# AE402FA0E5597BE0_CM55_HE_View register map
Vendor: Alif Semiconductor; Series: E4; File version: 1.0
CPU: CM55 r1p0, selectable endian, MPU, FPU, double-precision FPU, DSP, VTOR, 8 interrupt priority bits, 1 SAU regions
Registers are 32-bit, read-write, reset 0x0 unless marked. A register's access mark holds for its fields unless they carry their own. Offsets are from the block's base; [hi:lo] are bit positions; {n}, {i} and the like mark numbered series; <NAME> marks a mode.

## ETH (part 2 of 4)
Base 0x48100000
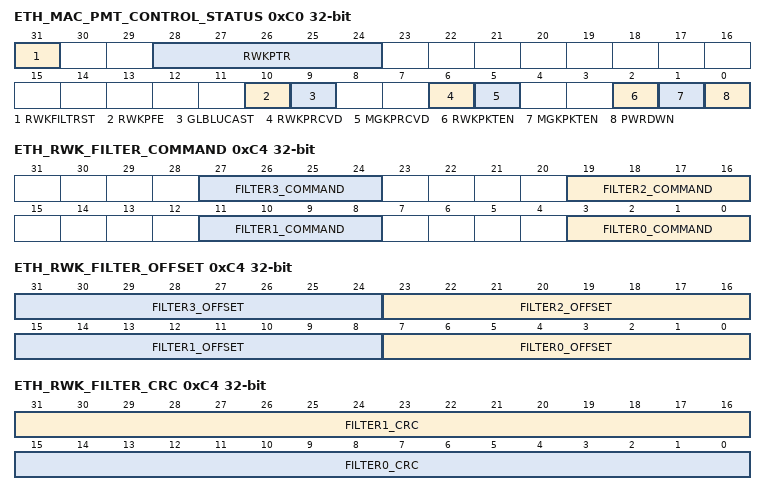
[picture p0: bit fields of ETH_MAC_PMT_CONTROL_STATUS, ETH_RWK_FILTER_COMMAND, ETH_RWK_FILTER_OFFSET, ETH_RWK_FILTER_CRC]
0xC0 ETH_MAC_PMT_CONTROL_STATUS — PMT Control and Status Register
  [31] RWKFILTRST — Remote Wake-Up Packet Filter Register Pointer Reset When this bit is set, the remote wake-up packet filter register pointer is reset to 0x0. It is automatically cleared after 1 clock cycle. Access restriction applies. Setting 1 sets. Self-cleared. Setting 0 has no effect.
    0=Remote wake-up packet filter register pointer is not reset; 1=Remote wake-up packet filter register pointer is reset
  [28:24] RWKPTR ro — Remote Wake-up FIFO Pointer This field gives the current value of the Remote Wake-up Packet Filter register pointer.
  [10] RWKPFE — Remote Wake-up Packet Forwarding Enable When this bit is set along with RWKPKTEN, the MAC receiver drops all received frames until it receives the expected wake-up frame. All frames after that event including the received wake-up frame are forwarded to application. This bit is then self-cleared on receiving the wake-up packet. The application can also clear this bit before the expected wake-up frame is received. In such cases, the MAC reverts to the default behavior where packets received are forwarded to the application. This bit must only be set when RWKPKTEN is set high and PWRDWN is set low. The setting of this bit has no effect when PWRDWN is set high. Note: If Magic Packet Enable and Wake-Up Frame Enable are both set along with setting of this bit and Magic Packet is received prior to wake-up frame, this bit is self-cleared on receiving Magic Packet, the received Magic packet is dropped, and all frames after received Magic Packet are forwarded to application. Access restriction applies. Setting 1 sets. Self-cleared. Setting 0 has no effect.
    0=Remote wake-up packet forwarding is disabled; 1=Remote wake-up packet forwarding is enabled
  [9] GLBLUCAST — Global Unicast When this bit set, any unicast packet filtered by the MAC (DAF) address recognition is detected as a remote wake-up packet.
    0=Global unicast is disabled; 1=Global unicast is enabled
  [6] RWKPRCVD ro — Remote Wake-Up Packet Received When this bit is set, it indicates that the power management event is generated because of the reception of a remote wake-up packet. This bit is cleared when this register is read. Access restriction applies. Clears on read or write of 1 when the ETH_MAC_CSR_SW_CTRL[RCWE] bit is set. Self-set to 1 on internal event.
    0=Remote wake-up packet is received; 1=Remote wake-up packet is received
  [5] MGKPRCVD ro — Magic Packet Received When this bit is set, it indicates that the power management event is generated because of the reception of a magic packet. This bit is cleared when this register is read. Access restriction applies. Clears on read or write of 1 when the ETH_MAC_CSR_SW_CTRL[RCWE] bit is set. Self-set to 1 on internal event.
    0=No magic packet is received; 1=Magic packet is received
  [2] RWKPKTEN — Remote Wake-Up Packet Enable When this bit is set, a power management event is generated when the MAC receives a remote wake-up packet.
    0=Remote wake-up packet is disabled; 1=Remote wake-up packet is enabled
  [1] MGKPKTEN — Magic Packet Enable When this bit is set, a power management event is generated when the MAC receives a magic packet.
    0=Magic packet is disabled; 1=Magic packet is enabled
  [0] PWRDWN — Power Down When this bit is set, the MAC receiver drops all received packets until it receives the expected magic packet or remote wake-up packet. This bit is then self-cleared and the power-down mode is disabled. The software can clear this bit before the expected magic packet or remote wake-up packet is received. The packets received by the MAC after this bit is cleared are forwarded to the application. This bit must only be set when the MGKPKTEN, GLBLUCAST, or RWKPKTEN bit is set high. Note: The user can gate-off the CLK_CSR during power-down mode. However, when the CLK_CSR is gated-off, the user cannot perform any read or write operations on this register. Therefore, software cannot clear this bit. Access restriction applies. Setting 1 sets. Self-cleared. Setting 0 has no effect.
    0=Power down is disabled; 1=Power down is enabled
0xC4 ETH_RWK_PACKET_FILTER — Remote Wakeup Filter Byte Mask Register
  [31:0] WKUPFRMFTR — RWK Packet Filter This field contains the various controls of RWK Packet filter.
0xC4 ETH_RWK_FILTER_BYTE_MASK (alternate view of ETH_RWK_PACKET_FILTER) — Remote Wakeup Filter Byte Mask Register
  [31:0] FILTER_BYTE_MASK — Filter0 to Filter3 32-bit Mask This field defines the bytes of the packet that are examined by the corresponding filter (0 to 3) to determine whether or not a packet is a wake-up packet. Bit 31 must be zero. Bits [30-0] are the byte mask. Each bit in this mask corresponds to one byte in the detected packet. If the bit is 1, the corresponding byte is taken into the CRC16 calculation.
0xC4 ETH_RWK_FILTER_COMMAND (alternate view of ETH_RWK_PACKET_FILTER) — Remote Wakeup Filter Command Register
  [8n+3:8n] FILTER{n}_COMMAND (n=0..3) — Filter{n} Command The 4-bit filter command controls the filter operation. Bit {8n+3} specifies the address type, defining the destination address type of the pattern. When the bit is set, the pattern applies to only multicast packets; when the bit is reset, the pattern applies only to unicast packet. Bit {8n+2} (Inverse Mode), when set, reverses the logic of the CRC16 hash function signal, to reject a packet with matching CRC_16 value. Bit {8n+2}, along with Bit {8n+1}, allows a MAC to reject a subset of remote wake-up packets by creating filter logic such as Pattern 1 AND NOT Pattern 2. Bit {8n+1} (And_Previous) implements the Boolean logic. When set, the result of the current entry is logically ANDed with the result of the previous filter. This AND logic allows a filter pattern longer than 32 bytes by splitting the mask among two, three, or four filters. This depends on the number of filters that have the And_Previous bit set. Bit {8n} is the enable for filter. If Bit {8n} is not set, filter is disabled.
0xC4 ETH_RWK_FILTER_OFFSET (alternate view of ETH_RWK_PACKET_FILTER) — Remote Wakeup Filter Offset Register
  [8n+7:8n] FILTER{n}_OFFSET (n=0..3) — Filter{n} Offset This filter offset defines the offset (within the packet) from which the filter examines the packets. This 8-bit pattern-offset is the offset for the filter first byte to be examined. The minimum allowed offset is 12, which refers to the 13th byte of the packet. The offset value 0 refers to the first byte of the packet.
0xC4 ETH_RWK_FILTER_CRC (alternate view of ETH_RWK_PACKET_FILTER) — Remote Wakeup Filter CRC-16 Register
  [31:16] FILTER1_CRC — Filter1 CRC-16 This filter CRC-16 contains the CRC_16 value of the pattern. The 16-bit CRC calculation uses the following polynomial: G(x) = x^16 + x^15 + x^2 + 1
  [15:0] FILTER0_CRC — Filter0 CRC-16 This filter CRC-16 contains the CRC_16 value of the pattern. The 16-bit CRC calculation uses the following polynomial: G(x) = x^16 + x^15 + x^2 + 1
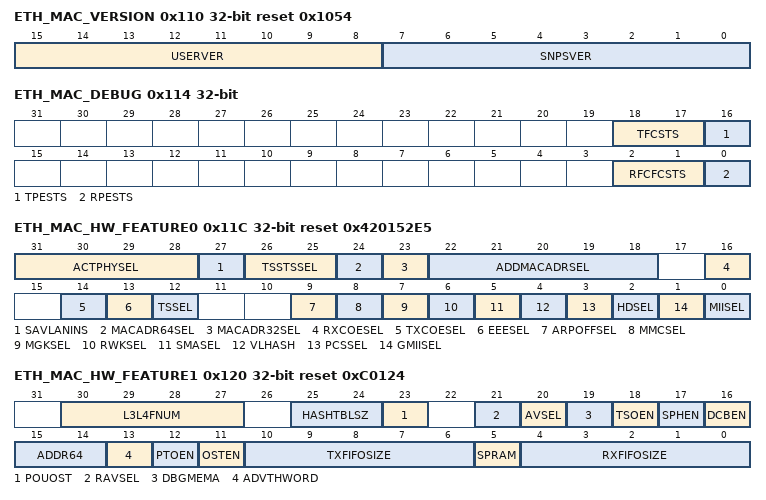
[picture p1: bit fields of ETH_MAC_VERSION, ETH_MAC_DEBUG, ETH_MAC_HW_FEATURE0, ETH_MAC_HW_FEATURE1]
0x110 ETH_MAC_VERSION ro reset 0x1054 — Module Version Register
  [15:8] USERVER — User-defined version
  [7:0] SNPSVER — Vendor-defined version
0x114 ETH_MAC_DEBUG ro — Debug Register
  [18:17] TFCSTS — Reserved
  [16] TPESTS — MAC RMII Transmit Protocol Engine Status When this bit is set, it indicates that the MAC RMII transmit protocol engine is actively transmitting data, and it is not in the Idle state.
    0=MAC RMII transmit protocol engine status not detected; 1=MAC RMII transmit protocol engine status detected
  [2:1] RFCFCSTS — Reserved
  [0] RPESTS — MAC RMII Receive Protocol Engine Status When this bit is set, it indicates that the MAC RMII receive protocol engine is actively receiving data, and it is not in the Idle state.
    0=MAC RMII receive protocol engine status not detected; 1=MAC RMII receive protocol engine status detected
0x11C ETH_MAC_HW_FEATURE0 ro reset 0x420152E5 — ETH Hardware Feature Register 0
  [31:28] ACTPHYSEL — Active PHY Selected
    4=RMII
  [27] SAVLANINS — Source Address or VLAN Insertion Enable
    0=Source address or VLAN insertion disabled
  [26:25] TSSTSSEL — Timestamp System Time Source
    1=Internal
  [24] MACADR64SEL — MAC Addresses 64-127 Selected
    0=MAC addresses 64-127 disabled
  [23] MACADR32SEL — MAC Addresses 32-63 Selected
    0=MAC addresses 32-63 disabled
  [22:18] ADDMACADRSEL — MAC Addresses 1-31 Selected
    0=MAC addresses 1-31 disabled
  [16] RXCOESEL — Receive Checksum Offload Enabled
    1=Receive checksum offload enabled
  [14] TXCOESEL — Transmit Checksum Offload Enabled
    1=Transmit checksum offload enabled
  [13] EEESEL — Energy Efficient Ethernet Enabled
    0=Energy efficient ethernet disabled
  [12] TSSEL — IEEE 1588-2008 Timestamp Enabled
    1=IEEE 1588-2008 timestamp enabled
  [9] ARPOFFSEL — ARP Offload Enabled
    1=ARP offload disabled
  [8] MMCSEL — RMON Module Enable
    0=RMON module disabled
  [7] MGKSEL — PMT Magic Packet Enable
    1=PMT magic packet enabled
  [6] RWKSEL — PMT Remote Wake-up Packet Enable
    1=PMT remote wake-up packet enabled
  [5] SMASEL — SMA (MDIO) Interface
    1=SMA (MDIO) interface selected
  [4] VLHASH — VLAN Hash Filter Selected
    0=VLAN hash filter not selected
  [3] PCSSEL — PCS Registers (TBI, SGMII, or RTBI PHY interface)
    0=No PCS registers (TBI, SGMII, or RTBI PHY interface)
  [2] HDSEL — Half-duplex Support
    1=Half-duplex supported
  [1] GMIISEL — 1000 Mbps Support
    0=No 1000 Mbps supported
  [0] MIISEL — 10 or 100 Mbps Support
    1=10 or 100 Mbps supported
0x120 ETH_MAC_HW_FEATURE1 ro reset 0xC0124 — ETH Hardware Feature Register 1
  [30:27] L3L4FNUM — Total number of L3 or L4 Filters
    0=No L3 or L4 filter
  [25:24] HASHTBLSZ — Hash Table Size
    0=No hash table
  [23] POUOST — One Step for PTP over UDP/IP Enable
    0=One step for PTP over UDP/IP is disabled
  [21] RAVSEL — Rx Side Only AV Enable
    0=Rx side only AV is disabled
  [20] AVSEL — AV Enable
    0=AV fature is disabled
  [19] DBGMEMA — DMA Debug Registers Enable
    1=DMA debug registers enabled
  [18] TSOEN — TCP Segmentation Offload Enable
    1=TCP segmentation offload is enabled
  [17] SPHEN — Split Header Enable
    0=Split header is disabled
  [16] DCBEN — DCB Enable
    0=DCB is not selected
  [15:14] ADDR64 — Address Width.
    0=32
  [13] ADVTHWORD — IEEE 1588 High Word Register Enable
    0=IEEE 1588 high word register is disabled
  [12] PTOEN — PTP Offload Enable
    0=PTP offload is disabled
  [11] OSTEN — One-Step Timestamping Enable
    0=One-step timestamping is disabled
  [10:6] TXFIFOSIZE — MTL Transmit FIFO Size
    4=2048 bytes
  [5] SPRAM — Single Port RAM Enable
    1=Single port RAM is enabled
  [4:0] RXFIFOSIZE — MTL Receive FIFO Size
    4=2048 bytes
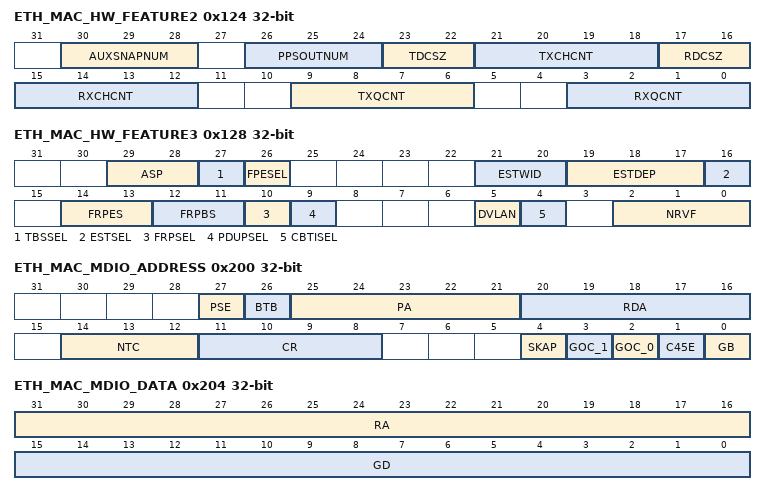
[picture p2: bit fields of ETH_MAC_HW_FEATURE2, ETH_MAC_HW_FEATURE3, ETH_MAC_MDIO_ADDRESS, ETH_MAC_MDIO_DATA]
0x124 ETH_MAC_HW_FEATURE2 ro — ETH Hardware Feature Register 2
  [30:28] AUXSNAPNUM — Number of Auxiliary Snapshot Inputs
    0=No auxiliary input
  [26:24] PPSOUTNUM — Number of PPS Outputs
    0=No PPS output
  [23:22] TDCSZ — Tx DMA Descriptor Cache Size in terms of 16-bytes descriptors
    0=Cache not configured
  [21:18] TXCHCNT — Number of DMA Transmit Channels
    0=1 DMA Tx channel
  [17:16] RDCSZ — Rx DMA Descriptor Cache Size in terms of 16-bytes descriptors
    0=Cache not configured
  [15:12] RXCHCNT — Number of DMA Receive Channels
    0=1 DMA Rx channel
  [9:6] TXQCNT — Number of MTL Transmit Queues
    0=1 MTL Tx Queue
  [3:0] RXQCNT — Number of MTL Receive Queues
    0=1 MTL Rx Queue
0x128 ETH_MAC_HW_FEATURE3 ro — ETH Hardware Feature Register 3
  [29:28] ASP — Automotive Safety Package
    0=No safety features selected
  [27] TBSSEL — Time Based Scheduling Enable
    0=Time based scheduling disabled
  [26] FPESEL — Frame Preemption Enable
    0=Frame preemption disabled
  [21:20] ESTWID — Width of the Time Interval field in the Gate Control List
    0=Width not configured
  [19:17] ESTDEP — Depth of the Gate Control List
    0=No depth configured
  [16] ESTSEL — Enhancements to Scheduled Traffic Enable
    0=Enhancements to scheduling traffic disabled
  [14:13] FRPES — Flexible Receive Parser Table Entries size
    0=64 entries
  [12:11] FRPBS — Flexible Receive Parser Buffer size
    0=64 bytes
  [10] FRPSEL — Flexible Receive Parser Select
    0=Flexible receive parser disabled
  [9] PDUPSEL — Broadcast/Multicast Packet Duplication
    0=Broadcast/multicast packet duplication disabled
  [5] DVLAN — Double VLAN Tag Processing Select
    0=Double VLAN tag processing disabled
  [4] CBTISEL — Queue/Channel based VLAN tag insertion on Tx Enable
    0=Queue/Channel based VLAN tag insertion on Tx disabled
  [2:0] NRVF — Number of Extended VLAN Tag Filters Enable
    0=No extended Rx VLAN filters
0x12C ETH_MAC_HW_FEATURE4 ro — ETH Hardware Feature Register 3
  [1:0] PCSEL — Policing Counters Selected
    0=Policing counter feature is not selected
0x200 ETH_MAC_MDIO_ADDRESS — MDIO Address Register
  [27] PSE — Preamble Suppression Enable When this bit is set, the MDIO suppresses the 32-bit preamble and transmits MDIO packets with only 1 preamble bit. When this bit is 0, the MDIO packets always has 32 bits of preamble as defined in the IEEE specifications.
    0=Preamble suppression disabled; 1=Preamble suppression enabled
  [26] BTB — Back to Back Transactions When this bit is set and if NTC > 0, at the end of the frame transfer, MAC acknowledges the completion of a read or write command before transferring the trailing clocks. So, application can initiate the next command and MAC can execute it immediately without waiting for the transmission of the trailing clocks of the previous frame. When this bit is reset, MAC considers the read or write command to be complete, that is, MAC clears the GB field, only after generating the trailing clocks. This mode ensures that the NTC is always generated after each frame. Note: Program this field with a value 1, only when NTC > 0.
    0=Back to back transactions disabled; 1=Back to back transactions enabled
  [25:21] PA — Physical Layer Address Specifies the address of the PHY device, out of the 32 possible PHY devices. Note: The value programmed in the C45E field determines if the PHY device is Clause 45 capable or Clause 22 capable.
  [20:16] RDA — Register or Device Address - For Clause 22 PHY: Specifies the PHY register address of the selected PHY device. - For Clause 45 PHY: Specifies the selected MDIO device.
  [14:12] NTC — Number of Trailing Clocks This field controls the number of trailing clock cycles generated on ETH_MDC after the end of MDIO frame transfer. The valid values can be from 0 to 7. When this field is programmed with a value of 0x3, MAC generates three clock cycles on the ETH_MDC line after the end of MDIO frame transfer.
  [11:8] CR — CSR Clock (CLK_CSR) Range The CLK_CSR range selection determines the frequency of the MDC clock (ETH_MDC) according to the CLK_CSR frequency: The suggested range of CLK_CSR frequency applicable for each value (when Bit 11 = 0) ensures that the ETH_MDC is approximately between 1.0 MHz to 2.5 MHz freqency range. When Bit 11 is set, the user can achieve a higher frequency of the ETH_MDC than the frequency limit of 2.5 MHz (specified in the IEEE 802.3 Specification) and program a clock divider of lower value. For example, when CLK_CSR is of 100 MHz frequency and the user programs the CR field to 0xA, the resultant ETH_MDC is of 12.5 MHz which is beyond the range specified in IEEE 802.3 Specification. Program the following values only if the interfacing chips support faster MDC clocks:
    0=CLK_CSR = 60-100 MHz; ETH_MDC = CLK_CSR / 42; 1=CLK_CSR = 100-150 MHz; ETH_MDC = CLK_CSR / 62; 2=CLK_CSR = 20-35 MHz; ETH_MDC = CLK_CSR / 16; 3=CLK_CSR = 35-60 MHz; ETH_MDC = CLK_CSR / 26; 4=CLK_CSR = 150-250 MHz; ETH_MDC = CLK_CSR / 102; 5=CLK_CSR = 250-300 MHz; ETH_MDC = CLK_CSR / 124; 6=CLK_CSR = 300-500 MHz; ETH_MDC = CLK_CSR / 204; 7=CLK_CSR = 500-800 MHz; ETH_MDC = CLK_CSR / 324; 8=CLK_CSR / 4; 9=CLK_CSR / 6; 10=CLK_CSR / 8; 11=CLK_CSR / 10; 12=CLK_CSR / 12; 13=CLK_CSR / 14; 14=CLK_CSR / 16; 15=CLK_CSR / 18
  [4] SKAP — Skip Address Packet When this bit is set, the MDIO does not send the address packets before read, write, or post-read increment address packets. This bit is valid only when the C45E bit is set.
    0=Skip address packet is disabled; 1=Skip address packet is enabled
  [3] GOC_1 — Operation Command 1 This is the higher bit of the operation command to the PHY. GOC_1 and GOC_O are encoded as follows: 0x0: Reserved 0x1: Write 0x2: Post read increment address for Clause 45 PHY 0x3: Read GOC_1 is encoded as follows: 0x0: Operation command 1 is disabled 0x1: Operation command 1 is enabled
  [2] GOC_0 — Operation Command 0 This is the lower bit of the operation command to the PHY. When in MDIO mode (MDIO master) this bit along with GOC_1 determines the operation to be performed to the PHY.
    0=Operation command 0 is disabled; 1=Operation command 0 is enabled
  [1] C45E — Clause 45 PHY Enable When this bit is set, Clause 45 capable PHY is connected to MDIO. When this bit is reset, Clause 22 capable PHY is connected to MDIO.
    0=Clause 45 PHY is disabled; 1=Clause 45 PHY is enabled
  [0] GB — RMII Busy The application writes 1 to this bit to instruct the SMA to initiate a read or write access to the MDIO slave. The MAC writes 0 to this bit after the MDIO frame transfer is complete. Therefore, the application must modify the fields of the ETH_MAC_MDIO_ADDRESS and ETH_MAC_MDIO_DATA registers only when the value in this bit is 0. For write operation, application must follow these steps: - Write the 16-bit data in the ETH_MAC_MDIO_DATA[GD] field. - Update the ETH_MAC_MDIO_DATA[RA] field with the register address of the PHY. - Write 1 to this bit For read operation, application must follow these steps: - Update the ETH_MAC_MDIO_DATA[RA] field with the register address of the PHY. - Write 1 to this bit - Wait until MAC writes 0 to this bit. When MAC writes 0 to this bit, it implies that the data read from the PHY is available in the ETH_MAC_MDIO_DATA[GD] field and the read transfer is complete. Note: RA field is valid only when C45E field is 1. Note: Even if the addressed PHY is not present, there is no change in the functionality of this bit. Access restriction applies. Setting 1 sets. Self-cleared. Setting 0 has no effect.
    0=RMII busy is disabled; 1=RMII busy is enabled
0x204 ETH_MAC_MDIO_DATA — MDIO Data Register
  [31:16] RA — Register Address This field is valid only when the ETH_MAC_MDIO_ADDRESS[C45E] bit is set. It contains the Register Address in the PHY to which the MDIO frame is intended for.
  [15:0] GD — RMII Data This field contains the 16-bit data value read from the PHY after a Management Read operation or the 16-bit data value to be written to the PHY before a Management Write operation.
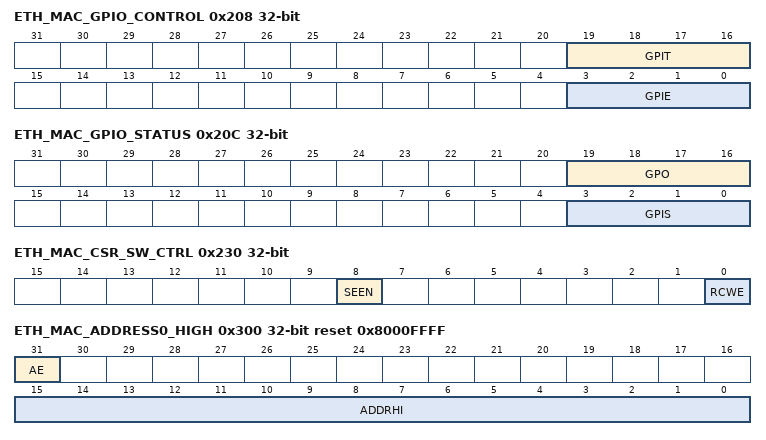
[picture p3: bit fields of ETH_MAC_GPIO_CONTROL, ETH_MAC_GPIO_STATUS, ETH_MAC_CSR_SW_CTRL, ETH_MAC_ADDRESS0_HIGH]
0x208 ETH_MAC_GPIO_CONTROL — GPIO Control Register
  [19:16] GPIT — GPI Type When a bit in this field is set, it indicates that the corresponding bit in the ETH_MAC_GPIO_STATUS[GPIS] field is of latched-low (LL) type. When a bit in this field is reset, it indicates that the corresponding bit in the ETH_MAC_GPIO_STATUS[GPIS] field is of latched-high (LH) type.
  [3:0] GPIE — GPI Interrupt Enable When a bit in this field is set and the programmed event (LL or LH) occurs on the corresponding bit in the ETH_MAC_GPIO_STATUS[GPIS] field, the ETH_MAC_INTERRUPT_STATUS[GPIIS] bit is set and an interrupt is generated on the ETH_SBD_IRQ signal. The ETH_MAC_INTERRUPT_STATUS[GPIIS] bit is cleared when the application reads the ETH_MAC_GPIO_STATUS[GPIS] field. When a bit in this field is reset, the ETH_MAC_INTERRUPT_STATUS[GPIIS] bit is not set when any event occurs on the corresponding bit in the ETH_MAC_GPIO_STATUS[GPIS] field.
0x20C ETH_MAC_GPIO_STATUS — GPIO Status Register
  [19:16] GPO — General Purpose Output When a bit in this field is set, it directly drives the corresponding bit of the GPO_O output port. When a bit in this field is reset, it does not directly drive the corresponding bit of the GPO_O output port.
  [3:0] GPIS — General Purpose Input Status This field gives the status of the signals connected to the GPI_I port. Each bit in this field is of the following types based on the setting of the corresponding bit in the ETH_MAC_GPIO_CONTROL[GPIT] field: - Latched-low (LL): This field is cleared when the corresponding GPI_I input becomes low. This field remains low until the application reads it after which this field reflects the current value of GPI_I input. - Latched-high (LH): This field is set when the corresponding GPI_I input becomes high. This field remains high until the application reads it after which this field reflects the current value of GPI_I input.
0x210 ETH_MAC_ARP_ADDRESS — ARP Address Register
  [31:0] ARPPA — ARP Protocol Address This field contains the IPv4 Destination Address of the MAC. This address is used for perfect match with the Protocol Address of Target field in the received ARP packet. This field is available only when the Enable IPv4 ARP Offload option is selected.
0x230 ETH_MAC_CSR_SW_CTRL — CSR Software Control Register
  [8] SEEN — Slave Error Response Enable When this bit is set, the MAC responds with Slave Error for accesses to reserved registers in CSR space. When this bit is reset, the MAC responds with OKAY response to any register accessed from CSR space.
    0=Slave error response is disabled; 1=Slave error response is enabled
  [0] RCWE — Register Clear on Write 1 Enable When this bit is set, the access mode of some register fields changes to Clear on Write 1, the application needs to set that respective bit to 1 to clear it. When this bit is reset, the access mode of these register fields remain as Clear on Read.
    0=Register clear on write 1 is disabled; 1=Register clear on write 1 is enabled
0x300 ETH_MAC_ADDRESS0_HIGH reset 0x8000FFFF — MAC Address 0 High Register
  [31] AE ro — Address Enable This bit is always set to 1.
    0=Ivalid. This bit must be always set to 1; 1=This bit is always set to 1
  [15:0] ADDRHI — MAC Address0[47-32] This field contains the upper 16 bits [47-32] of the first 6-byte MAC address. The MAC uses this field for filtering the received packets and inserting the MAC address in the Transmit Flow Control (Pause) Packets.
0x304 ETH_MAC_ADDRESS0_LOW reset 0xFFFFFFFF — MAC Address 0 Low Register
  [31:0] ADDRLO — MAC Address0[31-0] This field contains the lower 32 bits of the first 6-byte MAC address. The MAC uses this field for filtering the received packets and inserting the MAC address in the Transmit Flow Control (Pause) Packets.
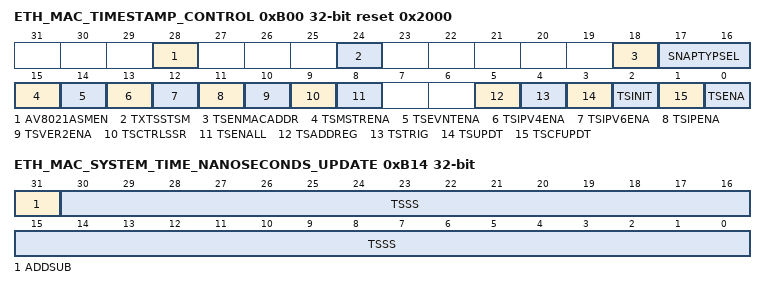
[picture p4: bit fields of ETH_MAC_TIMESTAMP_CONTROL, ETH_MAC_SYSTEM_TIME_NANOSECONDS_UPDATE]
0xB00 ETH_MAC_TIMESTAMP_CONTROL reset 0x2000 — Timestamp Control Register
  [28] AV8021ASMEN — AV 802.1AS Mode Enable When this bit is set, the MAC processes only untagged PTP over Ethernet packets for providing PTP status and capturing timestamp snapshots, that is, IEEE 802.1AS mode of operation.
    0=AV 802.1AS mode is disabled; 1=AV 802.1AS mode is enabled
  [24] TXTSSTSM — Transmit Timestamp Status Mode When this bit is set, the MAC overwrites the earlier transmit timestamp status even if it is not read by the software. The MAC indicates this by setting the ETH_MAC_TX_TIMESTAMP_STATUS_NANOSECONDS[TXTSSMIS] bit. When this bit is reset, the MAC ignores the timestamp status of current packet if the timestamp status of previous packet is not read by the software. The MAC indicates this by setting the ETH_MAC_TX_TIMESTAMP_STATUS_NANOSECONDS[TXTSSMIS] bit.
    0=Transmit timestamp status mode is disabled; 1=Transmit timestamp status mode is enabled
  [18] TSENMACADDR — Enable MAC Address for PTP Packet Filtering When this bit is set, the DA MAC address (that matches ETH_MAC_ADDRESS0_HIGH[ADDRHI] and ETH_MAC_ADDRESS0_LOW[ADDRLO]) is used to filter the PTP packets when PTP is directly sent over Ethernet. When this bit is set, received PTP packets with DA containing a special multicast or unicast address that matches the one programmed in the ETH_MAC_ADDRESS0_HIGH and ETH_MAC_ADDRESS0_LOW registers are considered for processing, when PTP is directly sent over Ethernet.
    0=MAC address for PTP packet filtering is disabled; 1=MAC address for PTP packet filtering is enabled
  [17:16] SNAPTYPSEL — Select PTP packets for Taking Snapshots This field, along with the TSMSTRENA and TSEVNTENA bits, decide the set of PTP packet types for which snapshot needs to be taken. The encoding is as follows: - SNAPTYPSEL = 0x0; TSMSTRENA = X; TSEVNTENA = 0x0: SYNC, Follow_Up, Delay_Req, Delay_Resp - SNAPTYPSEL = 0x0; TSMSTRENA = 0x0; TSEVNTENA = 0x1: SYNC - SNAPTYPSEL = 0x0; TSMSTRENA = 0x1; TSEVNTENA = 0x1: Delay_Req - SNAPTYPSEL = 0x1; TSMSTRENA = X; TSEVNTENA = 0x0: SYNC, Follow_Up, Delay_Req, Delay_Resp, Pdelay_Req, Pdelay_Resp, Pdelay_Resp_Follow_Up - SNAPTYPSEL = 0x1; TSMSTRENA = 0x0; TSEVNTENA = 0x1: SYNC, Pdelay_Req, Pdelay_Resp - SNAPTYPSEL = 0x1; TSMSTRENA = 0x1; TSEVNTENA = 0x1: Delay_Req, Pdelay_Req, Pdelay_Resp - SNAPTYPSEL = 0x2; TSMSTRENA = X; TSEVNTENA = X: SYNC, Delay_Req - SNAPTYPSEL = 0x3; TSMSTRENA = X; TSEVNTENA = X: Pdelay_Req, Pdelay_Resp Note: X means 'don't care'.
  [15] TSMSTRENA — Enable Snapshot for Messages Relevant to Master When this bit is set, the snapshot is taken only for the messages that are relevant to the master node. Otherwise, the snapshot is taken for the messages relevant to the slave node.
    0=Snapshot for messages relevant to master is disabled; 1=Snapshot for messages relevant to master is enabled
  [14] TSEVNTENA — Enable Timestamp Snapshot for Event Messages When this bit is set, the timestamp snapshot is taken only for event messages (SYNC, Delay_Req, Pdelay_Req, or Pdelay_Resp). When this bit is reset, the snapshot is taken for all messages except Announce, Management, and Signaling.
    0=Timestamp snapshot for event messages is disabled; 1=Timestamp snapshot for event messages is enabled
  [13] TSIPV4ENA — Enable Processing of PTP Packets Sent over IPv4-UDP When this bit is set, the MAC receiver processes the PTP packets encapsulated in IPv4-UDP packets. When this bit is reset, the MAC ignores the PTP transported over IPv4-UDP packets. This bit is set by default.
    0=Processing of PTP packets sent over IPv4-UDP is disabled; 1=Processing of PTP packets sent over IPv4-UDP is enabled
  [12] TSIPV6ENA — Enable Processing of PTP Packets Sent over IPv6-UDP When this bit is set, the MAC receiver processes the PTP packets encapsulated in IPv6-UDP packets. When this bit is clear, the MAC ignores the PTP transported over IPv6-UDP packets.
    0=Processing of PTP packets sent over IPv6-UDP is disabled; 1=Processing of PTP packets sent over IPv6-UDP is enabled
  [11] TSIPENA — Enable Processing of PTP over Ethernet Packets When this bit is set, the MAC receiver processes the PTP packets encapsulated directly in the Ethernet packets. When this bit is reset, the MAC ignores the PTP over Ethernet packets.
    0=Processing of PTP over Ethernet packets is disabled; 1=Processing of PTP over Ethernet packets is enabled
  [10] TSVER2ENA — Enable PTP Packet Processing for Version 2 Format When this bit is set, the IEEE 1588 version 2 format is used to process the PTP packets. When this bit is reset, the IEEE 1588 version 1 format is used to process the PTP packets.
    0=PTP packet processing for version 2 format is disabled; 1=PTP packet processing for version 2 format is enabled
  [9] TSCTRLSSR — Timestamp Digital or Binary Rollover Control When this bit is set, the ETH_MAC_SYSTEM_TIME_NANOSECONDS register rolls over after 0x3B9A_C9FF value (that is, 1 nanosecond accuracy) and increments the ETH_MAC_SYSTEM_TIME_SECONDS register. When this bit is reset, the rollover value of the ETH_MAC_SYSTEM_TIME_NANOSECONDS register is 0x7FFF_FFFF. The sub-second increment must be programmed correctly depending on the CLK_PTP frequency and the value of this bit.
    0=Timestamp digital or binary rollover control is disabled; 1=Timestamp digital or binary rollover control is enabled
  [8] TSENALL — Enable Timestamp for All Packets When this bit is set, the timestamp snapshot is enabled for all packets received by the MAC.
    0=Timestamp for all packets disabled; 1=Timestamp for all packets enabled
  [5] TSADDREG — Update the ETH_MAC_TIMESTAMP_ADDEND register When this bit is set, the content of the ETH_MAC_TIMESTAMP_ADDEND register is updated in the PTP block for fine correction. This bit is cleared when the update is complete. This bit must be zero before it is set. Access restriction applies. Setting 1 sets. Self-cleared. Setting 0 has no effect.
    0=Addend register is not updated; 1=Addend register is updated
  [4] TSTRIG — Enable Timestamp Interrupt Trigger When this bit is set, the timestamp interrupt is generated when the System Time becomes greater than the value written in the Target Time register. This bit is reset after the Timestamp Trigger Interrupt is generated. Access restriction applies. Setting 1 sets. Self-cleared. Setting 0 has no effect.
    0=Timestamp interrupt trigger is not enabled; 1=Timestamp interrupt trigger is enabled
  [3] TSUPDT — Update Timestamp When this bit is set, the system time is updated (added or subtracted) with the value specified in ETH_MAC_SYSTEM_TIME_SECONDS_UPDATE and ETH_MAC_SYSTEM_TIME_NANOSECONDS_UPDATE registers. This bit must be zero before updating it. This bit is reset when the update is complete in hardware. Access restriction applies. Setting 1 sets. Self-cleared. Setting 0 has no effect.
    0=Timestamp is not updated; 1=Timestamp is updated
  [2] TSINIT — Initialize Timestamp When this bit is set, the system time is initialized (overwritten) with the value specified in the ETH_MAC_SYSTEM_TIME_SECONDS_UPDATE and ETH_MAC_SYSTEM_TIME_NANOSECONDS_UPDATE registers. This bit must be zero before it is updated. This bit is reset when the initialization is complete. Only the ETH_MAC_SYSTEM_TIME_SECONDS register can be initialized. Access restriction applies. Setting 1 sets. Self-cleared. Setting 0 has no effect.
    0=Timestamp is not initialized; 1=Timestamp is initialized
  [1] TSCFUPDT — Fine or Coarse Timestamp Update When this bit is set, the Fine method is used to update system timestamp. When this bit is reset, Coarse method is used to update the system timestamp.
    0=Coarse method is used to update system timestamp; 1=Fine method is used to update system timestamp
  [0] TSENA — Enable Timestamp When this bit is set, the timestamp is added for Transmit and Receive packets. When disabled, timestamp is not added for transmit and receive packets and the Timestamp Generator is also suspended. The user needs to initialize the Timestamp (system time) after enabling this mode. On the Receive side, the MAC processes the 1588 packets only if this bit is set.
    0=Timestamp is disabled; 1=Timestamp is enabled
0xB04 ETH_MAC_SUB_SECOND_INCREMENT — Sub-second Increment Register
  [23:16] SSINC — Sub-second Increment Value The value programmed in this field is accumulated every clock cycle (of CLK_PTP) with the contents of the ETH_MAC_SYSTEM_TIME_NANOSECONDS register. For example, when the PTP clock is 50 MHz (period is 20 ns), the user must program 20 (0x14) when the ETH_MAC_SYSTEM_TIME_NANOSECONDS register has an accuracy of 1 ns (the ETH_MAC_TIMESTAMP_CONTROL[TSCTRLSSR] bit is set). When TSCTRLSSR is cleard, the ETH_MAC_SYSTEM_TIME_NANOSECONDS register has a resolution of ~0.465 ns. In this case, the user must program a value of 43 (0x2B) which is derived by 20 ns/0.465.
0xB08 ETH_MAC_SYSTEM_TIME_SECONDS ro — System Time Seconds Register
  [31:0] TSS — Timestamp Second The value in this field indicates the current value in seconds of the System Time maintained by the MAC.
0xB0C ETH_MAC_SYSTEM_TIME_NANOSECONDS ro — System Time Nanoseconds Register
  [30:0] TSSS — Timestamp Sub Seconds The value in this field has the sub-second representation of time, with an accuracy of 0.46 ns. When the ETH_MAC_TIMESTAMP_CONTROL[TSCTRLSSR] bit is set, each bit represents 1 ns. The maximum value is 0x3B9A_C9FF after which it rolls-over to zero.
0xB10 ETH_MAC_SYSTEM_TIME_SECONDS_UPDATE — System Time Seconds Update Register
  [31:0] TSS — Timestamp Seconds The value in this field is the seconds part of the update. When ETH_MAC_SYSTEM_TIME_NANOSECONDS_UPDATE[ADDSUB] is reset, this field must be programmed with the seconds part of the update value. When ETH_MAC_SYSTEM_TIME_NANOSECONDS_UPDATE[ADDSUB] is set, this field must be programmed with the complement of the seconds part of the update value. For example, to subtract 2.000000001 seconds from the system time, the TSS field must be 0xFFFF_FFFE (that is, 2^32 - 2).
0xB14 ETH_MAC_SYSTEM_TIME_NANOSECONDS_UPDATE — System Time Nanoseconds Update Register
  [31] ADDSUB — Add or Subtract Time When this bit is set, the time value is subtracted with the contents of the update register. When this bit is reset, the time value is added with the contents of the update register.
    0=Add time; 1=Subtract time
  [30:0] TSSS — Timestamp Sub Seconds The value in this field is the sub-seconds part of the update. When ETH_MAC_SYSTEM_TIME_NANOSECONDS_UPDATE[ADDSUB] is reset, this field must be programmed with the sub-seconds part of the update value, with an accuracy based on the ETH_MAC_TIMESTAMP_CONTROL[TSCTRLSSR] bit. When ETH_MAC_SYSTEM_TIME_NANOSECONDS_UPDATE[ADDSUB] is set, this field must be programmed with the complement of the sub-seconds part of the update value as described below. When the ETH_MAC_TIMESTAMP_CONTROL[TSCTRLSSR] bit set, the programmed value must be 10^9 - <sub-second value>. When the ETH_MAC_TIMESTAMP_CONTROL[TSCTRLSSR] bit reset, the programmed value must be 2^31 - <sub-second_value>. When the TSCTRLSSR bit is reset in the ETH_MAC_TIMESTAMP_CONTROL register, each bit represents an accuracy of 0.46 ns. When the TSCTRLSSR bit is set in the ETH_MAC_TIMESTAMP_CONTROL register, each bit represents 1 ns and the programmed value should not exceed 0x3B9A_C9FF. For example, to subtract 2.000000001 seconds from the system time, then the TSSS field must be 0x7FFF_FFFF (that is, 2^31 - 1), when the ETH_MAC_TIMESTAMP_CONTROL[TSCTRLSSR] bit reset and 0x3B9A_C9FF (that is, 10^9 - 1), when the ETH_MAC_TIMESTAMP_CONTROL[TSCTRLSSR] bit set.
